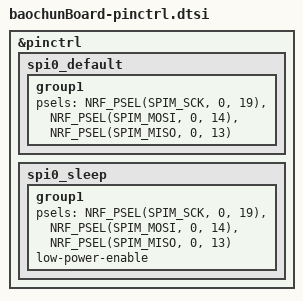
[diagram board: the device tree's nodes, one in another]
// ECG OVERLAY
&pinctrl {
    spi0_default: spi0_default {
		group1 {
			psels = <NRF_PSEL(SPIM_SCK, 0, 19)>,
				<NRF_PSEL(SPIM_MOSI, 0, 14)>,
				<NRF_PSEL(SPIM_MISO, 0, 13)>;
		};
	};

	spi0_sleep: spi0_sleep {
		group1 {
			psels = <NRF_PSEL(SPIM_SCK, 0, 19)>,
				<NRF_PSEL(SPIM_MOSI, 0, 14)>,
				<NRF_PSEL(SPIM_MISO, 0, 13)>;
			low-power-enable;
		};
	};
};



